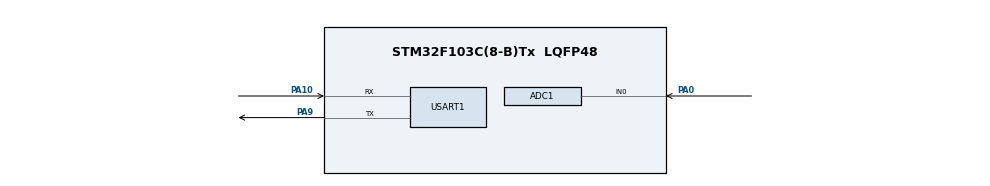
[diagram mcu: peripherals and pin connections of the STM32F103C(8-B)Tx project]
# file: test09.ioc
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ADC1.Channel-0\#ChannelRegularConversion=ADC_CHANNEL_0
ADC1.NbrOfConversionFlag=1
ADC1.Rank-0\#ChannelRegularConversion=1
ADC1.SamplingTime-0\#ChannelRegularConversion=ADC_SAMPLETIME_1CYCLE_5
ADC1.master=1
FREERTOS.BinarySemaphores01=myBinarySem01,Dynamic,NULL,Available
FREERTOS.Tasks01=DefaultTask,24,128,StartDefaultTask,Default,NULL,Dynamic,NULL,NULL;myTask02,41,128,StartTask02,Default,NULL,Dynamic,NULL,NULL;myTask03,42,128,StartTask03,Default,NULL,Dynamic,NULL,NULL
FREERTOS.configUSE_NEWLIB_REENTRANT=1
Mcu.Family=STM32F1
Mcu.Name=STM32F103C(8-B)Tx
Mcu.Package=LQFP48
NVIC.ADC1_2_IRQn=true\:5\:0\:false\:false\:true\:true\:true\:true\:true
NVIC.PriorityGroup=NVIC_PRIORITYGROUP_4
NVIC.TIM1_UP_IRQn=true\:15\:0\:false\:false\:true\:false\:false\:true\:true
NVIC.TimeBase=TIM1_UP_IRQn
NVIC.TimeBaseIP=TIM1
NVIC.USART1_IRQn=true\:5\:0\:false\:false\:true\:true\:true\:true\:true
PA0-WKUP.Signal=ADCx_IN0
PA10.Mode=Asynchronous
PA10.Signal=USART1_RX
PA13.Mode=Serial_Wire
PA13.Signal=SYS_JTMS-SWDIO
PA14.Mode=Serial_Wire
PA14.Signal=SYS_JTCK-SWCLK
PA9.Mode=Asynchronous
PA9.Signal=USART1_TX
ProjectManager.HeapSize=0x200
ProjectManager.StackSize=0x400
ProjectManager.TargetToolchain=STM32CubeIDE
RCC.APB1Freq_Value=8000000
RCC.APB2Freq_Value=8000000
SH.ADCx_IN0.0=ADC1_IN0,IN0
USART1.VirtualMode=VM_ASYNC
VP_FREERTOS_VS_CMSIS_V2.Mode=CMSIS_V2
VP_SYS_VS_tim1.Mode=TIM1
board=custom

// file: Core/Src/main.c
/* USER CODE BEGIN Header */
/**
  ******************************************************************************
  * @file           : main.c
  * @brief          : Main program body
  ******************************************************************************
  * @attention
  *
  * Copyright (c) 2025 STMicroelectronics.
  * All rights reserved.
  *
  * This software is licensed under terms that can be found in the LICENSE file
  * in the root directory of this software component.
  * If no LICENSE file comes with this software, it is provided AS-IS.
  *
  ******************************************************************************
  */
/* USER CODE END Header */
#include "main.h"
#include "cmsis_os.h"

ADC_HandleTypeDef hadc1;

UART_HandleTypeDef huart1;

/* Definitions for DefaultTask */
osThreadId_t DefaultTaskHandle;
const osThreadAttr_t DefaultTask_attributes = {
  .name = "DefaultTask",
  .stack_size = 128 * 4,
  .priority = (osPriority_t) osPriorityNormal,
};
/* Definitions for myTask02 */
osThreadId_t myTask02Handle;
const osThreadAttr_t myTask02_attributes = {
  .name = "myTask02",
  .stack_size = 128 * 4,
  .priority = (osPriority_t) osPriorityHigh1,
};
/* Definitions for myTask03 */
osThreadId_t myTask03Handle;
const osThreadAttr_t myTask03_attributes = {
  .name = "myTask03",
  .stack_size = 128 * 4,
  .priority = (osPriority_t) osPriorityHigh2,
};
/* Definitions for myBinarySem01 */
osSemaphoreId_t myBinarySem01Handle;
const osSemaphoreAttr_t myBinarySem01_attributes = {
  .name = "myBinarySem01"
};

void SystemClock_Config(void);
static void MX_GPIO_Init(void);
static void MX_ADC1_Init(void);
static void MX_USART1_UART_Init(void);
void StartDefaultTask(void *argument);
void StartTask02(void *argument);
void StartTask03(void *argument);

int main(void)
{

  /* MCU Configuration--------------------------------------------------------*/

  /* Reset of all peripherals, Initializes the Flash interface and the Systick. */
  HAL_Init();

  /* Configure the system clock */
  SystemClock_Config();

  /* Initialize all configured peripherals */
  MX_GPIO_Init();
  MX_ADC1_Init();
  MX_USART1_UART_Init();

  /* Init scheduler */
  osKernelInitialize();

  /* Create the semaphores(s) */
  /* creation of myBinarySem01 */
  myBinarySem01Handle = osSemaphoreNew(1, 1, &myBinarySem01_attributes);

  /* Create the thread(s) */
  /* creation of DefaultTask */
  DefaultTaskHandle = osThreadNew(StartDefaultTask, NULL, &DefaultTask_attributes);

  /* creation of myTask02 */
  myTask02Handle = osThreadNew(StartTask02, NULL, &myTask02_attributes);

  /* creation of myTask03 */
  myTask03Handle = osThreadNew(StartTask03, NULL, &myTask03_attributes);

  /* Start scheduler */
  osKernelStart();

  /* We should never get here as control is now taken by the scheduler */

  /* Infinite loop */
  while (1)
  {

  }
}

void SystemClock_Config(void)
{
  RCC_OscInitTypeDef RCC_OscInitStruct = {0};
  RCC_ClkInitTypeDef RCC_ClkInitStruct = {0};
  RCC_PeriphCLKInitTypeDef PeriphClkInit = {0};

  /** Initializes the RCC Oscillators according to the specified parameters
  * in the RCC_OscInitTypeDef structure.
  */
  RCC_OscInitStruct.OscillatorType = RCC_OSCILLATORTYPE_HSI;
  RCC_OscInitStruct.HSIState = RCC_HSI_ON;
  RCC_OscInitStruct.HSICalibrationValue = RCC_HSICALIBRATION_DEFAULT;
  RCC_OscInitStruct.PLL.PLLState = RCC_PLL_NONE;
  if (HAL_RCC_OscConfig(&RCC_OscInitStruct) != HAL_OK)
  {
    Error_Handler();
  }

  /** Initializes the CPU, AHB and APB buses clocks
  */
  RCC_ClkInitStruct.ClockType = RCC_CLOCKTYPE_HCLK|RCC_CLOCKTYPE_SYSCLK
                              |RCC_CLOCKTYPE_PCLK1|RCC_CLOCKTYPE_PCLK2;
  RCC_ClkInitStruct.SYSCLKSource = RCC_SYSCLKSOURCE_HSI;
  RCC_ClkInitStruct.AHBCLKDivider = RCC_SYSCLK_DIV1;
  RCC_ClkInitStruct.APB1CLKDivider = RCC_HCLK_DIV1;
  RCC_ClkInitStruct.APB2CLKDivider = RCC_HCLK_DIV1;

  if (HAL_RCC_ClockConfig(&RCC_ClkInitStruct, FLASH_LATENCY_0) != HAL_OK)
  {
    Error_Handler();
  }
  PeriphClkInit.PeriphClockSelection = RCC_PERIPHCLK_ADC;
  PeriphClkInit.AdcClockSelection = RCC_ADCPCLK2_DIV2;
  if (HAL_RCCEx_PeriphCLKConfig(&PeriphClkInit) != HAL_OK)
  {
    Error_Handler();
  }
}

static void MX_ADC1_Init(void)
{

  ADC_ChannelConfTypeDef sConfig = {0};

  /** Common config
  */
  hadc1.Instance = ADC1;
  hadc1.Init.ScanConvMode = ADC_SCAN_DISABLE;
  hadc1.Init.ContinuousConvMode = DISABLE;
  hadc1.Init.DiscontinuousConvMode = DISABLE;
  hadc1.Init.ExternalTrigConv = ADC_SOFTWARE_START;
  hadc1.Init.DataAlign = ADC_DATAALIGN_RIGHT;
  hadc1.Init.NbrOfConversion = 1;
  if (HAL_ADC_Init(&hadc1) != HAL_OK)
  {
    Error_Handler();
  }

  /** Configure Regular Channel
  */
  sConfig.Channel = ADC_CHANNEL_0;
  sConfig.Rank = ADC_REGULAR_RANK_1;
  sConfig.SamplingTime = ADC_SAMPLETIME_1CYCLE_5;
  if (HAL_ADC_ConfigChannel(&hadc1, &sConfig) != HAL_OK)
  {
    Error_Handler();
  }

}

static void MX_USART1_UART_Init(void)
{

  huart1.Instance = USART1;
  huart1.Init.BaudRate = 115200;
  huart1.Init.WordLength = UART_WORDLENGTH_8B;
  huart1.Init.StopBits = UART_STOPBITS_1;
  huart1.Init.Parity = UART_PARITY_NONE;
  huart1.Init.Mode = UART_MODE_TX_RX;
  huart1.Init.HwFlowCtl = UART_HWCONTROL_NONE;
  huart1.Init.OverSampling = UART_OVERSAMPLING_16;
  if (HAL_UART_Init(&huart1) != HAL_OK)
  {
    Error_Handler();
  }

}

static void MX_GPIO_Init(void)
{

  /* GPIO Ports Clock Enable */
  __HAL_RCC_GPIOA_CLK_ENABLE();

}

void StartDefaultTask(void *argument)
{
  for(;;)
  {
    osDelay(1);
  }
}

void StartTask02(void *argument)
{
  /* USER CODE BEGIN StartTask02 */
  /* Infinite loop */
  for(;;)
  {
  if (osSemaphoreAcquire(myBinarySem01Handle, osWaitForever) == osOK) {
	  // Thực hiện công việc của Task 2
	  const char* in_task=" Task 2 in....\r\n";
	  uint32_t tick = HAL_GetTick();
	  char tick_str[20]; // Tạo buffer để chứa chuỗi
	  sprintf(tick_str, "%lu", tick); // Chuyển tick thành chuỗi (dạng số không dấu)
	  HAL_UART_Transmit(&huart1, (uint8_t*)tick_str, strlen(tick_str), HAL_MAX_DELAY);
	  HAL_UART_Transmit(&huart1, in_task, strlen(in_task), HAL_MAX_DELAY);
	  osDelay(1000);
  }
//    osDelay(1);
  }
  /* USER CODE END StartTask02 */
}

void StartTask03(void *argument)
{
  /* USER CODE BEGIN StartTask03 */
  /* Infinite loop */
  for(;;)
  {
  if (osSemaphoreAcquire(myBinarySem01Handle, osWaitForever) == osOK) {
	  // Thực hiện công việc của Task 3
	  const char* in_task=" Task 3 in....\r\n";
	  uint32_t tick = HAL_GetTick();
	  char tick_str[20]; // Tạo buffer để chứa chuỗi
	  sprintf(tick_str, "%lu", tick); // Chuyển tick thành chuỗi (dạng số không dấu)
	  HAL_UART_Transmit(&huart1, (uint8_t*)tick_str, strlen(tick_str), HAL_MAX_DELAY);
	  HAL_UART_Transmit(&huart1, in_task, strlen(in_task), HAL_MAX_DELAY);
	  osDelay(500);
	}
  }
  /* USER CODE END StartTask03 */
}

void HAL_TIM_PeriodElapsedCallback(TIM_HandleTypeDef *htim)
{
  if (htim->Instance == TIM1) {
    HAL_IncTick();
  }
  /* USER CODE BEGIN Callback 1 */
  if (htim->Instance == TIM1) { // Kiểm tra Timer 2
          osSemaphoreRelease(myBinarySem01Handle); // Kích hoạt Semaphore
      }
  /* USER CODE END Callback 1 */
}

void Error_Handler(void)
{
  __disable_irq();
  while (1)
  {
  }
}
